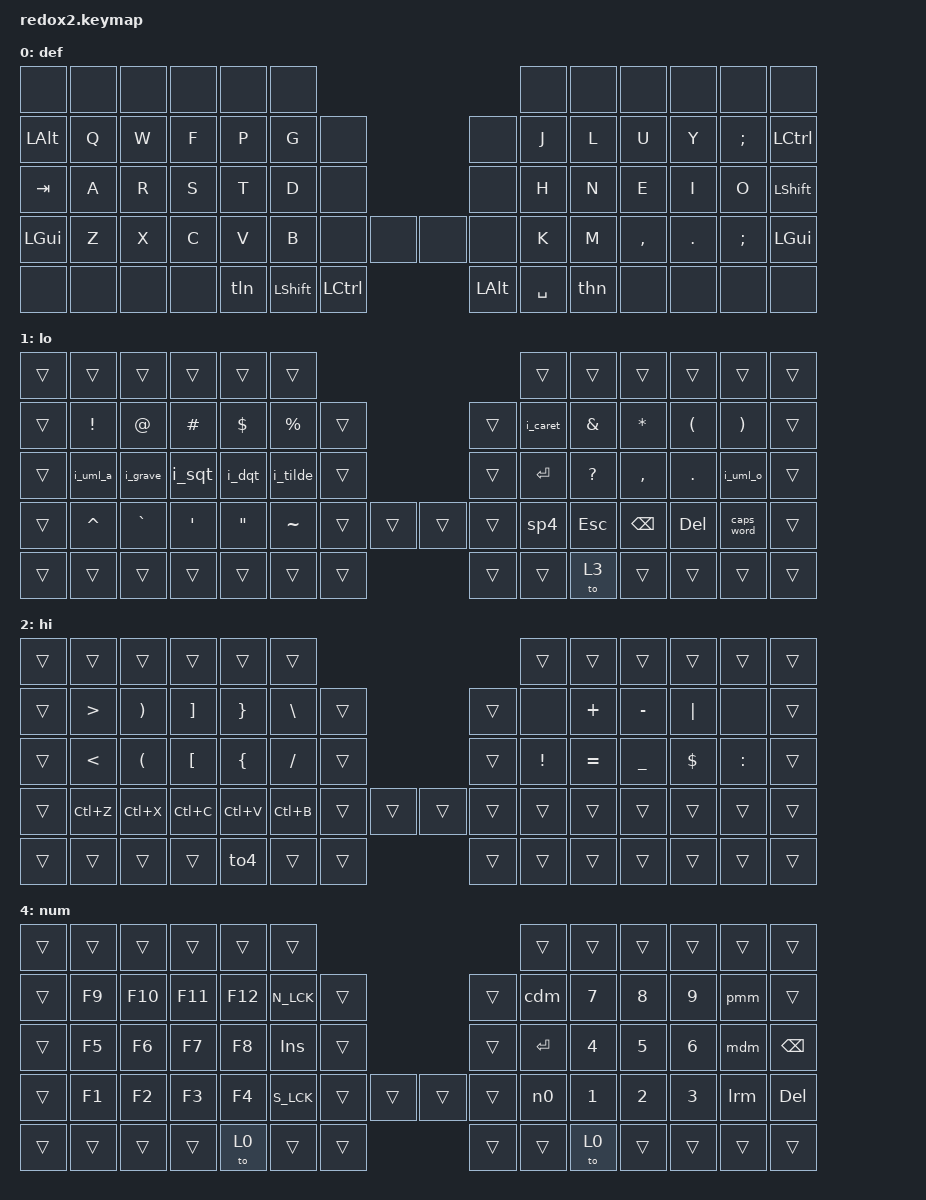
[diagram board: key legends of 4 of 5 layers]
/*
 * Copyright (c) 2021 The ZMK Contributors
 *
 * SPDX-License-Identifier: MIT
 */

#include <behaviors.dtsi>
#include <dt-bindings/zmk/keys.h>
#include <dt-bindings/zmk/bt.h>
#include <dt-bindings/zmk/ext_power.h>
#include <dt-bindings/zmk/outputs.h>

/ {
    behaviors {
        i_ua: i_uml_a {
            compatible = "zmk,behavior-macro";
            #binding-cells = <0>;
            bindings = <&macro_tap &kp DQT>, <&macro_tap &kp A>;
        };
        i_uo: i_uml_o {
            compatible = "zmk,behavior-macro";
            #binding-cells = <0>;
            bindings = <&macro_tap &kp DQT>, <&macro_tap &kp O>;
        };
        i_dt: i_double_quote {
            compatible = "zmk,behavior-macro";
            #binding-cells = <0>;
            bindings = <&macro_tap &kp DQT>, <&macro_tap &kp SPACE>;
        };
        i_st: i_single_quote {
            compatible = "zmk,behavior-macro";
            #binding-cells = <0>;
            bindings = <&macro_tap &kp SQT>, <&macro_tap &kp SPACE>;
        };
        i_gr: i_grave {
            compatible = "zmk,behavior-macro";
            #binding-cells = <0>;
            bindings = <&macro_tap &kp GRAVE>, <&macro_tap &kp SPACE>;
        };
        i_td: i_tilde {
            compatible = "zmk,behavior-macro";
            #binding-cells = <0>;
            bindings = <&macro_tap &kp TILDE>, <&macro_tap &kp SPACE>;
        };
        i_ct: i_caret {
            compatible = "zmk,behavior-macro";
            #binding-cells = <0>;
            bindings= <&macro_tap &kp CARET>, <&macro_tap &kp SPACE>;
        };

        sp4: four_spaces {
            compatible = "zmk,behavior-macro";
            #binding-cells = <0>;
            bindings = <&macro_tap &kp SPACE &kp SPACE &kp SPACE &kp SPACE>;
        };
        bnm: bt_next_mod {
            compatible = "zmk,behavior-macro";
            #binding-cells = <0>;
            bindings = <&none>, &bt BT_NXT>;
            mods = <(MOD_LGUI|MOD_LSFT|MOD_LALT|MOD_LCTRL)>;
        };
        bpm: bt_prev_mod {
            compatible = "zmk,behavior-macro";
            #binding-cells = <0>;
            bindings = <&none>, &bt BT_NXT>;
            mods = <(MOD_LGUI|MOD_LSFT|MOD_LALT|MOD_LCTRL)>;
        };
        bcm: bt_clr_mod {
            compatible = "zmk,behavior-mod-morph";
            #binding-cells = <0>;
            bindings = <&none>, <&bt BT_CLR>;
            mods = <(MOD_LGUI|MOD_LSFT|MOD_LALT|MOD_LCTRL)>;
        };
        otm: out_tog_mod {
            compatible = "zmk,behavior-macro";
            #binding-cells = <0>;
            bindings = <&none>, &out OUT_TOG>;
            mods = <(MOD_LGUI|MOD_LSFT|MOD_LALT|MOD_LCTRL)>;
        };

        pmm: plus_minus_mod {
            compatible = "zmk,behavior-mod-morph";
            #binding-cells = <0>;
            bindings = <&kp KP_PLUS>, <&kp KP_MINUS>;
            mods = <(MOD_LGUI|MOD_LSFT|MOD_LALT|MOD_LCTRL)>;
        };
        mdm: mp_div_mod {
            compatible = "zmk,behavior-mod-morph";
            #binding-cells = <0>;
            bindings = <&kp KP_MULTIPLY>, <&kp KP_DIVIDE>;
            mods = <(MOD_LGUI|MOD_LSFT|MOD_LALT|MOD_LCTRL)>;
        };
        cdm: comma_dot_mod {
            compatible = "zmk,behavior-mod-morph";
            #binding-cells = <0>;
            bindings = <&kp KP_COMMA>, <&kp KP_DOT>;
            mods = <(MOD_LGUI|MOD_LSFT|MOD_LALT|MOD_LCTRL)>;
        };
        lrm: lpar_rpar_mod {
            compatible = "zmk,behavior-mod-morph";
            #binding-cells = <0>;
            bindings = <&kp KP_LPAR>, <&kp KP_RPAR>;
            mods = <(MOD_LGUI|MOD_LSFT|MOD_LALT|MOD_LCTRL)>;
        };

        thn: tap_dance_hi_nav {
            compatible = "zmk, behavior-tap-dance";
            #binding-cells = <0>;
            tapping-term-ms = <200>;
            bindings = <&mo 2>, <&to 3>;
        };
        tln: tap_dance_lo_num {
            compatible = "zmk, behavior-tap-dance";
            #binding-cells = <0>;
            tapping-term-ms = <200>;
            bindings = <&mo 1>, <&to 4>;
        };

    };
};

&caps_word {
    continue-list = <
                    UNDERSCORE
                    MINUS
                    DELETE
                    BACKSPACE
                    >;
};

/ {
    keymap {
        compatible =  "zmk,keymap" ;

        def {
// -------------------------------------------------------------------------------------------------------
// |     |     |     |     |     |     |     |     | --- |     |     |     |     |     |     |     |     |
// | ALT |  Q  |  W  |  F  |  P  |  G  |     |     | --- |     |     |  J  |  L  |  U  |  Y  |  ;  | CTL |
// | TAB |  A  |  R  |  S  |  T  |  D  |     |     | --- |     |     |  H  |  N  |  E  |  I  |  O  | SFT |
// | GUI |  Z  |  X  |  C  |  V  |  B  |     |     | --- |     |     |  K  |  M  |  ,  |  .  |  ;  | GUI |
// |     |     |     |     |   MO-LO   | SFT | CTL | --- | ALT | SPC |   MO-HI   |     |     |     |     |
            bindings = <
   &none     &none  &none  &none  &none  &none                                             &none   &none   &none      &none     &none     &none
   &kp LALT  &kp Q  &kp W  &kp F  &kp P  &kp G  &none                           &none      &kp J   &kp L   &kp U      &kp Y     &kp SEMI  &kp LCTRL
   &kp TAB   &kp A  &kp R  &kp S  &kp T  &kp D  &none                           &none      &kp H   &kp N   &kp E      &kp I     &kp O     &kp LSHFT
   &kp LGUI  &kp Z  &kp X  &kp C  &kp V  &kp B  &none      &none      &none     &none      &kp K   &kp M   &kp COMMA  &kp DOT   &kp SEMI  &kp LGUI
   &none     &none  &none  &none      &tln      &kp LSHFT  &kp LCTRL  &kp LALT  &kp SPACE      &thn        &none      &none     &none     &none
            >;

        };

        lo {  // left hand bottom row chars are 'raw' and can be used to create intl chars like ä with us.intl layout
// -------------------------------------------------------------------------------------------------------
// |     |     |     |     |     |     |     |     | --- |     |     |     |     |     |     |     |     |
// | ALT |  !  |  @  |  #  |  $  |  %  |     |     | --- |     |     |  ^  |  &  |  *  |  (  |  )  | CTL |
// | TAB |  Ä  |  `  |  '  |  "  |  ~  |     |     | --- |     |     | RET |  ?  |  ,  |  .  |  Ö  | SFT |
// | GUI |  ^  |  `  |  '  |  "  |  ~  |     |     | --- |     |     | 4sp | ESC | BSP | DEL | CAP | GUI |
// |     |     |     |     |           | SFT | CTL | --- | ALT | SPC |   TONAV   |     |     |     |     |
            bindings = <
   &trans   &trans     &trans     &trans    &trans    &trans                                       &trans    &trans     &trans     &trans    &trans      &trans
   &trans   &kp EXCL   &kp AT     &kp HASH  &kp DLLR  &kp PRCNT  &trans                    &trans  &i_caret  &kp AMPS   &kp ASTRK  &kp LPAR  &kp RPAR    &trans
   &trans   &i_uml_a   &i_grave   &i_sqt    &i_dqt    &i_tilde   &trans                    &trans  &kp RET   &kp QMARK  &kp COMMA  &kp DOT   &i_uml_o    &trans
   &trans   &kp CARET  &kp GRAVE  &kp SQT   &kp DQT   &kp TILDE  &trans   &trans   &trans  &trans  &sp4      &kp ESC    &kp BKSP   &kp DEL   &caps_word  &trans
   &trans   &trans     &trans     &trans          &trans         &trans   &trans   &trans  &trans        &to 3          &trans     &trans   &trans      &trans
            >;
        };

        hi {
// -------------------------------------------------------------------------------------------------------
// |     |     |     |     |     |     |     |     | --- |     |     |     |     |     |     |     |     |
// | ALT |  >  |  )  |  ]  |  }  |  \  |     |     | --- |     |     |     |  +  |  -  |  |  |     | CTL |
// | TAB |  <  |  (  |  [  |  {  |  /  |     |     | --- |     |     | RET |  =  |  _  |  $  |  :  | SFT |
// | GUI | C+Z | C+X | C+C | C+V | C+B |     |     | --- |     |     | 4sp | ESC | BSP | DEL | CAP | GUI |
// |     |     |     |     |   TONUM   | SFT | CTL | --- | ALT | SPC |           |     |     |     |     |
            bindings = <
   &trans  &trans     &trans     &trans     &trans     &trans                                     &trans    &trans     &trans     &trans    &trans     &trans
   &trans  &kp GT     &kp RPAR   &kp RBKT   &kp RBRC   &kp BSLH   &trans                  &trans  &none     &kp PLUS   &kp MINUS  &kp PIPE  &none      &trans
   &trans  &kp LT     &kp LPAR   &kp LBKT   &kp LBRC   &kp FSLH   &trans                  &trans  &kp EXCL  &kp EQUAL  &kp UNDER  &kp DLLR  &kp COLON  &trans
   &trans  &kp LC(Z)  &kp LC(X)  &kp LC(C)  &kp LC(V)  &kp LC(B)  &trans  &trans  &trans  &trans  &trans    &trans     &trans     &trans    &trans     &trans
   &trans  &trans     &trans     &trans             &to4          &trans  &trans  &trans  &trans        &trans         &trans     &trans    &trans     &trans
            >;
       };

        nav {  // bts and output toggle must use some modifier ALT, CTRL, SHIFT
// -------------------------------------------------------------------------------------------------------
// |     |      |     |      |     |     |     |     | --- |     |     |     |     |     |     |     |     |
// | ALT | BTD  |     | BTP  | BTN | OTG |     |     | --- |     |     |     | PGU | UP  | PGD | HME | CTL |
// | TAB | ASTB | ATB | CSTB | CTB | SST |     |     | --- |     |     | RET | LFT | DWN | RGT | END | SFT |
// | GUI | C+Z  | C+X | C+C  | C+V | C+B |     |     | --- |     |     | 4sp | ESC | BSP | DEL | CAP | GUI |
// |     |      |     |      |   TODEF   | SFT | CTL | --- | ALT | SPC |   TODEF   |     |     |     |     |
            bindings = <
   &trans  &trans           &trans       &trans           &trans       &trans                                     &trans  &trans     &trans     &trans     &trans     &trans
   &trans  &bcm             &none        &bpm             &bnm         &otm       &trans                  &trans  &none   &kp PG_UP  &kp UP     &kp PG_DN  &kp HOME   &trans
   &trans  &kp LA(LS(TAB))  &kp LA(TAB)  &kp LC(LS(TAB))  &kp LC(TAB)  &kp PSCRN  &trans                  &trans  &trans  &kp LEFT   &kp DOWN   &kp RIGHT  &kp END    &trans
   &trans  &kp LC(Z)        &kp LC(X)    &kp LC(C)        &kp LC(V)    &kp LC(B)  &trans  &trans  &trans  &trans  &trans  &trans     &trans     &trans     &trans     &trans
   &trans  &trans           &trans       &trans        &to 0           &trans     &trans  &trans  &trans  &trans       &to 0         &trans     &trans     &trans     &trans
            >;
        };

        num {  // +;*;(;, to -;/;);. with any modifier ALT, CTRL, SHIFT
// -------------------------------------------------------------------------------------------------------
// |     |    |     |     |     |     |     |     | --- |     |     |     |     |     |      |     |     |
// | ALT | F9 | F10 | F11 | F12 | NLK |     |     | --- |     |     | ,;. |  7  |  8  |  9   | +;- | CTL |
// | TAB | F5 | F6  | F7  | F8  | INS |     |     | --- |     |     | RET |  4  |  5  |  6   | *;/ | BSP |
// | GUI | F1 | F2  | F3  | F4  | SLK |     |     | --- |     |     |  0  |  1  |  2  |  3   | (;) | DEL |
// |     |    |     |     |   TODEF   | SFT | CTL | --- | ALT | SPC |   TODEF   |     |      |     |     |
            bindings = <
   &trans  &trans  &trans   &trans  &trans   &trans                                     &trans   &trans   &trans  &trans  &trans  &trans
   &trans  &kp F9  &kp F10  &kp F11 &kp F12  &kp N_LCK  &trans                  &trans  &cdm     &kp N7   &kp N8  &kp N9  &pmm    &trans
   &trans  &kp F5  &kp F6   &kp F7  &kp F8   &kp INS    &trans                  &trans  &kp RET  &kp N4   &kp N5  &kp N6  &mdm    &kp BKSP
   &trans  &kp F1  &kp F2   &kp F3  &kp F4   &kp S_LCK  &trans  &trans  &trans  &trans  &kp n0   &kp N1   &kp N2  &kp N3  &lrm    &kp DEL
   &trans  &trans  &trans   &trans       &to 0          &trans  &trans  &trans  &trans        &to 0       &trans  &trans  &trans  &trans
            >;
        };
    };
};
